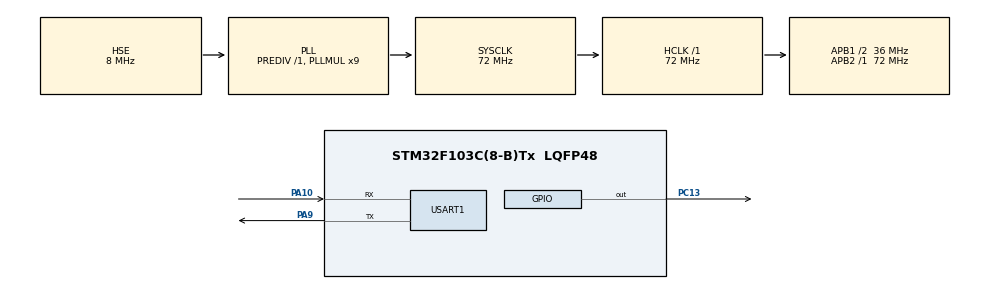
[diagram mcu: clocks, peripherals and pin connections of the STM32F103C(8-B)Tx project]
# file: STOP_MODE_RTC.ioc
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Mcu.Family=STM32F1
Mcu.Name=STM32F103C(8-B)Tx
Mcu.Package=LQFP48
NVIC.PriorityGroup=NVIC_PRIORITYGROUP_4
NVIC.RTC_Alarm_IRQn=true\:0\:0\:false\:false\:true\:true\:true
PA10.Mode=Asynchronous
PA10.Signal=USART1_RX
PA13.Mode=Serial_Wire
PA13.Signal=SYS_JTMS-SWDIO
PA14.Mode=Serial_Wire
PA14.Signal=SYS_JTCK-SWCLK
PA9.Mode=Asynchronous
PA9.Signal=USART1_TX
PC13-TAMPER-RTC.Signal=GPIO_Output
PC14-OSC32_IN.Mode=LSE-External-Oscillator
PC14-OSC32_IN.Signal=RCC_OSC32_IN
PC15-OSC32_OUT.Mode=LSE-External-Oscillator
PC15-OSC32_OUT.Signal=RCC_OSC32_OUT
PD0-OSC_IN.Mode=HSE-External-Oscillator
PD0-OSC_IN.Signal=RCC_OSC_IN
PD1-OSC_OUT.Mode=HSE-External-Oscillator
PD1-OSC_OUT.Signal=RCC_OSC_OUT
ProjectManager.HeapSize=0x200
ProjectManager.StackSize=0x400
ProjectManager.TargetToolchain=STM32CubeIDE
RCC.AHBFreq_Value=72000000
RCC.APB1CLKDivider=RCC_HCLK_DIV2
RCC.APB1Freq_Value=36000000
RCC.APB1TimFreq_Value=72000000
RCC.APB2Freq_Value=72000000
RCC.APB2TimFreq_Value=72000000
RCC.HCLKFreq_Value=72000000
RCC.PLLMUL=RCC_PLL_MUL9
RCC.PLLSourceVirtual=RCC_PLLSOURCE_HSE
RCC.RTCClockSelection=RCC_RTCCLKSOURCE_LSE
RCC.SYSCLKFreq_VALUE=72000000
RCC.SYSCLKSource=RCC_SYSCLKSOURCE_PLLCLK
RCC.USBFreq_Value=72000000
RTC.Format=RTC_FORMAT_BIN
USART1.VirtualMode=VM_ASYNC
VP_RTC_VS_RTC_Activate.Mode=RTC_Enabled
VP_RTC_VS_RTC_Calendar.Mode=RTC_Calendar
board=custom

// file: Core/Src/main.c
/* USER CODE BEGIN Header */
/**
  ******************************************************************************
  * @file           : main.c
  * @brief          : Main program body
  ******************************************************************************
  * @attention
  *
  * <h2><center>&copy; Copyright (c) 2021 STMicroelectronics.
  * All rights reserved.</center></h2>
  *
  * This software component is licensed by ST under BSD 3-Clause license,
  * the "License"; You may not use this file except in compliance with the
  * License. You may obtain a copy of the License at:
  *                        opensource.org/licenses/BSD-3-Clause
  *
  ******************************************************************************
  */
/* USER CODE END Header */
#include "main.h"

/* USER CODE BEGIN PD */
#define SLEEP_TIME		10U
/* USER CODE END PD */

RTC_HandleTypeDef hrtc;

UART_HandleTypeDef huart1;

/* USER CODE BEGIN PV */

uint8_t alarm_flag = 0;

/* USER CODE END PV */

void SystemClock_Config(void);
static void MX_GPIO_Init(void);
static void MX_RTC_Init(void);
static void MX_USART1_UART_Init(void);
/* USER CODE BEGIN PFP */

void setAlarm(void);
void resetTime(void);
void HAL_RTC_AlarmAEventCallback(RTC_HandleTypeDef *hrtc);   //This routine is called when alarm interrupt occurs
void enterStopMode(void);
/* USER CODE END PFP */

int main(void)
{

  /* MCU Configuration--------------------------------------------------------*/

  /* Reset of all peripherals, Initializes the Flash interface and the Systick. */
  HAL_Init();

  /* Configure the system clock */
  SystemClock_Config();

  /* Initialize all configured peripherals */
  MX_GPIO_Init();
  MX_RTC_Init();
  MX_USART1_UART_Init();
  /* USER CODE BEGIN 2 */
  resetTime();
  setAlarm();
//  uint8_t msg[] = "Startup...\r\n";
//  HAL_UART_Transmit(&huart1, msg, sizeof(msg), 1000);

  LED_ON();
  HAL_Delay(1000);
  LED_OFF();

  enterStopMode();
  /* USER CODE END 2 */

  /* Infinite loop */
  while (1)
  {

    /* USER CODE BEGIN 3 */
	RTC_TimeTypeDef sTime;
    HAL_RTC_GetTime(&hrtc, &sTime, RTC_FORMAT_BIN); //To see the timing for debug
    if (alarm_flag)
    {
        alarm_flag = 0;
        resetTime();
        setAlarm();
        enterStopMode();
    }
  }
  /* USER CODE END 3 */
}

void SystemClock_Config(void)
{
  RCC_OscInitTypeDef RCC_OscInitStruct = {0};
  RCC_ClkInitTypeDef RCC_ClkInitStruct = {0};
  RCC_PeriphCLKInitTypeDef PeriphClkInit = {0};

  /** Initializes the RCC Oscillators according to the specified parameters
  * in the RCC_OscInitTypeDef structure.
  */
  RCC_OscInitStruct.OscillatorType = RCC_OSCILLATORTYPE_HSE|RCC_OSCILLATORTYPE_LSE;
  RCC_OscInitStruct.HSEState = RCC_HSE_ON;
  RCC_OscInitStruct.HSEPredivValue = RCC_HSE_PREDIV_DIV1;
  RCC_OscInitStruct.LSEState = RCC_LSE_ON;
  RCC_OscInitStruct.HSIState = RCC_HSI_ON;
  RCC_OscInitStruct.PLL.PLLState = RCC_PLL_ON;
  RCC_OscInitStruct.PLL.PLLSource = RCC_PLLSOURCE_HSE;
  RCC_OscInitStruct.PLL.PLLMUL = RCC_PLL_MUL9;
  if (HAL_RCC_OscConfig(&RCC_OscInitStruct) != HAL_OK)
  {
    Error_Handler();
  }
  /** Initializes the CPU, AHB and APB buses clocks
  */
  RCC_ClkInitStruct.ClockType = RCC_CLOCKTYPE_HCLK|RCC_CLOCKTYPE_SYSCLK
                              |RCC_CLOCKTYPE_PCLK1|RCC_CLOCKTYPE_PCLK2;
  RCC_ClkInitStruct.SYSCLKSource = RCC_SYSCLKSOURCE_PLLCLK;
  RCC_ClkInitStruct.AHBCLKDivider = RCC_SYSCLK_DIV1;
  RCC_ClkInitStruct.APB1CLKDivider = RCC_HCLK_DIV2;
  RCC_ClkInitStruct.APB2CLKDivider = RCC_HCLK_DIV1;

  if (HAL_RCC_ClockConfig(&RCC_ClkInitStruct, FLASH_LATENCY_2) != HAL_OK)
  {
    Error_Handler();
  }
  PeriphClkInit.PeriphClockSelection = RCC_PERIPHCLK_RTC;
  PeriphClkInit.RTCClockSelection = RCC_RTCCLKSOURCE_LSE;
  if (HAL_RCCEx_PeriphCLKConfig(&PeriphClkInit) != HAL_OK)
  {
    Error_Handler();
  }
}

static void MX_RTC_Init(void)
{

  RTC_TimeTypeDef sTime = {0};
  RTC_DateTypeDef DateToUpdate = {0};

  /** Initialize RTC Only
  */
  hrtc.Instance = RTC;
  hrtc.Init.AsynchPrediv = RTC_AUTO_1_SECOND;
  hrtc.Init.OutPut = RTC_OUTPUTSOURCE_NONE;
  if (HAL_RTC_Init(&hrtc) != HAL_OK)
  {
    Error_Handler();
  }

  /** Initialize RTC and set the Time and Date
  */
  sTime.Hours = 0;
  sTime.Minutes = 0;
  sTime.Seconds = 0;

  if (HAL_RTC_SetTime(&hrtc, &sTime, RTC_FORMAT_BIN) != HAL_OK)
  {
    Error_Handler();
  }
  DateToUpdate.WeekDay = RTC_WEEKDAY_MONDAY;
  DateToUpdate.Month = RTC_MONTH_JANUARY;
  DateToUpdate.Date = 1;
  DateToUpdate.Year = 0;

  if (HAL_RTC_SetDate(&hrtc, &DateToUpdate, RTC_FORMAT_BIN) != HAL_OK)
  {
    Error_Handler();
  }

}

static void MX_USART1_UART_Init(void)
{

  huart1.Instance = USART1;
  huart1.Init.BaudRate = 115200;
  huart1.Init.WordLength = UART_WORDLENGTH_8B;
  huart1.Init.StopBits = UART_STOPBITS_1;
  huart1.Init.Parity = UART_PARITY_NONE;
  huart1.Init.Mode = UART_MODE_TX_RX;
  huart1.Init.HwFlowCtl = UART_HWCONTROL_NONE;
  huart1.Init.OverSampling = UART_OVERSAMPLING_16;
  if (HAL_UART_Init(&huart1) != HAL_OK)
  {
    Error_Handler();
  }

}

static void MX_GPIO_Init(void)
{
  GPIO_InitTypeDef GPIO_InitStruct = {0};

  /* GPIO Ports Clock Enable */
  __HAL_RCC_GPIOC_CLK_ENABLE();
  __HAL_RCC_GPIOD_CLK_ENABLE();
  __HAL_RCC_GPIOA_CLK_ENABLE();

  /*Configure GPIO pin Output Level */
  HAL_GPIO_WritePin(GPIOC, GPIO_PIN_13, GPIO_PIN_RESET);

  /*Configure GPIO pin : PC13 */
  GPIO_InitStruct.Pin = GPIO_PIN_13;
  GPIO_InitStruct.Mode = GPIO_MODE_OUTPUT_PP;
  GPIO_InitStruct.Pull = GPIO_NOPULL;
  GPIO_InitStruct.Speed = GPIO_SPEED_FREQ_LOW;
  HAL_GPIO_Init(GPIOC, &GPIO_InitStruct);

}

/* USER CODE BEGIN 4 */

void HAL_RTC_AlarmAEventCallback(RTC_HandleTypeDef *hrtc)
{
    alarm_flag = 1;
}
void enterStopMode(void)
{
    __HAL_PWR_CLEAR_FLAG(PWR_FLAG_WU);
 	HAL_PWR_EnterSTANDBYMode();
}

void setAlarm(void)
{
    RTC_AlarmTypeDef sAlarm;

    sAlarm.AlarmTime.Hours = 0U;
    sAlarm.AlarmTime.Minutes = 0U;
    sAlarm.AlarmTime.Seconds = SLEEP_TIME;
    sAlarm.Alarm = RTC_ALARM_A;

    if (HAL_RTC_SetAlarm_IT(&hrtc, &sAlarm, RTC_FORMAT_BIN) != HAL_OK)
    {
	   Error_Handler();
    }
}

void resetTime(void)
{
    RTC_TimeTypeDef sTime;

    sTime.Hours = 0U;
    sTime.Minutes = 0U;
    sTime.Seconds = 0U;

    if (HAL_RTC_SetTime(&hrtc, &sTime, RTC_FORMAT_BCD) != HAL_OK)
    {
        Error_Handler();
    }
}
/* USER CODE END 4 */

void Error_Handler(void)
{
  __disable_irq();
  while (1)
  {
  }
}

/************************ (C) COPYRIGHT STMicroelectronics *****END OF FILE****/
